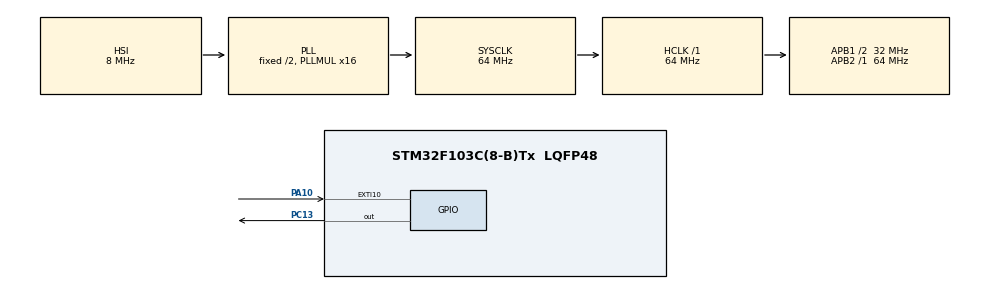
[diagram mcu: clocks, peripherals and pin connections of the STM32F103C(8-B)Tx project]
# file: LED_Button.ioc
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Mcu.Family=STM32F1
Mcu.Name=STM32F103C(8-B)Tx
Mcu.Package=LQFP48
NVIC.EXTI15_10_IRQn=true\:0\:0\:false\:false\:true\:true
NVIC.PriorityGroup=NVIC_PRIORITYGROUP_4
NVIC.TIM2_IRQn=true\:0\:0\:false\:false\:true\:true
PA10.GPIO_PuPd=GPIO_PULLUP
PA10.Signal=GPXTI10
PA13.Mode=Serial_Wire
PA13.Signal=SYS_JTMS-SWDIO
PA14.Mode=Serial_Wire
PA14.Signal=SYS_JTCK-SWCLK
PC13-TAMPER-RTC.Signal=GPIO_Output
ProjectManager.HeapSize=0x200
ProjectManager.StackSize=0x400
ProjectManager.TargetToolchain=TrueSTUDIO
RCC.AHBFreq_Value=64000000
RCC.APB1CLKDivider=RCC_HCLK_DIV2
RCC.APB1Freq_Value=32000000
RCC.APB1TimFreq_Value=64000000
RCC.APB2Freq_Value=64000000
RCC.APB2TimFreq_Value=64000000
RCC.HCLKFreq_Value=64000000
RCC.PLLMUL=RCC_PLL_MUL16
RCC.SYSCLKFreq_VALUE=64000000
RCC.SYSCLKSource=RCC_SYSCLKSOURCE_PLLCLK
RCC.USBFreq_Value=64000000
TIM2.Period=999
TIM2.Prescaler=31999
VP_TIM2_VS_ClockSourceINT.Mode=Internal
board=custom

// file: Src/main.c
/* USER CODE BEGIN Header */
/**
  ******************************************************************************
  * @file           : main.c
  * @brief          : Main program body
  ******************************************************************************
  ** This notice applies to any and all portions of this file
  * that are not between comment pairs USER CODE BEGIN and
  * USER CODE END. Other portions of this file, whether
  * inserted by the user or by software development tools
  * are owned by their respective copyright owners.
  *
  * COPYRIGHT(c) 2019 STMicroelectronics
  *
  * Redistribution and use in source and binary forms, with or without modification,
  * are permitted provided that the following conditions are met:
  *   1. Redistributions of source code must retain the above copyright notice,
  *      this list of conditions and the following disclaimer.
  *   2. Redistributions in binary form must reproduce the above copyright notice,
  *      this list of conditions and the following disclaimer in the documentation
  *      and/or other materials provided with the distribution.
  *   3. Neither the name of STMicroelectronics nor the names of its contributors
  *      may be used to endorse or promote products derived from this software
  *      without specific prior written permission.
  *
  * THIS SOFTWARE IS PROVIDED BY THE COPYRIGHT HOLDERS AND CONTRIBUTORS "AS IS"
  * AND ANY EXPRESS OR IMPLIED WARRANTIES, INCLUDING, BUT NOT LIMITED TO, THE
  * IMPLIED WARRANTIES OF MERCHANTABILITY AND FITNESS FOR A PARTICULAR PURPOSE ARE
  * DISCLAIMED. IN NO EVENT SHALL THE COPYRIGHT HOLDER OR CONTRIBUTORS BE LIABLE
  * FOR ANY DIRECT, INDIRECT, INCIDENTAL, SPECIAL, EXEMPLARY, OR CONSEQUENTIAL
  * DAMAGES (INCLUDING, BUT NOT LIMITED TO, PROCUREMENT OF SUBSTITUTE GOODS OR
  * SERVICES; LOSS OF USE, DATA, OR PROFITS; OR BUSINESS INTERRUPTION) HOWEVER
  * CAUSED AND ON ANY THEORY OF LIABILITY, WHETHER IN CONTRACT, STRICT LIABILITY,
  * OR TORT (INCLUDING NEGLIGENCE OR OTHERWISE) ARISING IN ANY WAY OUT OF THE USE
  * OF THIS SOFTWARE, EVEN IF ADVISED OF THE POSSIBILITY OF SUCH DAMAGE.
  *
  ******************************************************************************
  */
/* USER CODE END Header */

#include "main.h"

TIM_HandleTypeDef htim2;

void SystemClock_Config(void);
static void MX_GPIO_Init(void);
static void MX_TIM2_Init(void);

int main(void)
{

  /* MCU Configuration--------------------------------------------------------*/

  /* Reset of all peripherals, Initializes the Flash interface and the Systick. */
  HAL_Init();

  /* Configure the system clock */
  SystemClock_Config();

  /* Initialize all configured peripherals */
  MX_GPIO_Init();
  MX_TIM2_Init();
  /* USER CODE BEGIN 2 */
  HAL_TIM_Base_Start_IT(&htim2);
  /* USER CODE END 2 */

  /* Infinite loop */
  while (1)
  {

  }
}

void SystemClock_Config(void)
{
  RCC_OscInitTypeDef RCC_OscInitStruct = {0};
  RCC_ClkInitTypeDef RCC_ClkInitStruct = {0};

  /**Initializes the CPU, AHB and APB busses clocks
  */
  RCC_OscInitStruct.OscillatorType = RCC_OSCILLATORTYPE_HSI;
  RCC_OscInitStruct.HSIState = RCC_HSI_ON;
  RCC_OscInitStruct.HSICalibrationValue = RCC_HSICALIBRATION_DEFAULT;
  RCC_OscInitStruct.PLL.PLLState = RCC_PLL_ON;
  RCC_OscInitStruct.PLL.PLLSource = RCC_PLLSOURCE_HSI_DIV2;
  RCC_OscInitStruct.PLL.PLLMUL = RCC_PLL_MUL16;
  if (HAL_RCC_OscConfig(&RCC_OscInitStruct) != HAL_OK)
  {
    Error_Handler();
  }
  /**Initializes the CPU, AHB and APB busses clocks
  */
  RCC_ClkInitStruct.ClockType = RCC_CLOCKTYPE_HCLK|RCC_CLOCKTYPE_SYSCLK
                              |RCC_CLOCKTYPE_PCLK1|RCC_CLOCKTYPE_PCLK2;
  RCC_ClkInitStruct.SYSCLKSource = RCC_SYSCLKSOURCE_PLLCLK;
  RCC_ClkInitStruct.AHBCLKDivider = RCC_SYSCLK_DIV1;
  RCC_ClkInitStruct.APB1CLKDivider = RCC_HCLK_DIV2;
  RCC_ClkInitStruct.APB2CLKDivider = RCC_HCLK_DIV1;

  if (HAL_RCC_ClockConfig(&RCC_ClkInitStruct, FLASH_LATENCY_2) != HAL_OK)
  {
    Error_Handler();
  }
}

static void MX_TIM2_Init(void)
{

  TIM_ClockConfigTypeDef sClockSourceConfig = {0};
  TIM_MasterConfigTypeDef sMasterConfig = {0};

  htim2.Instance = TIM2;
  htim2.Init.Prescaler = 31999;
  htim2.Init.CounterMode = TIM_COUNTERMODE_UP;
  htim2.Init.Period = 999;
  htim2.Init.ClockDivision = TIM_CLOCKDIVISION_DIV1;
  htim2.Init.AutoReloadPreload = TIM_AUTORELOAD_PRELOAD_DISABLE;
  if (HAL_TIM_Base_Init(&htim2) != HAL_OK)
  {
    Error_Handler();
  }
  sClockSourceConfig.ClockSource = TIM_CLOCKSOURCE_INTERNAL;
  if (HAL_TIM_ConfigClockSource(&htim2, &sClockSourceConfig) != HAL_OK)
  {
    Error_Handler();
  }
  sMasterConfig.MasterOutputTrigger = TIM_TRGO_RESET;
  sMasterConfig.MasterSlaveMode = TIM_MASTERSLAVEMODE_DISABLE;
  if (HAL_TIMEx_MasterConfigSynchronization(&htim2, &sMasterConfig) != HAL_OK)
  {
    Error_Handler();
  }

}

static void MX_GPIO_Init(void)
{
  GPIO_InitTypeDef GPIO_InitStruct = {0};

  /* GPIO Ports Clock Enable */
  __HAL_RCC_GPIOC_CLK_ENABLE();
  __HAL_RCC_GPIOA_CLK_ENABLE();

  /*Configure GPIO pin Output Level */
  HAL_GPIO_WritePin(GPIOC, GPIO_PIN_13, GPIO_PIN_RESET);

  /*Configure GPIO pin : PC13 */
  GPIO_InitStruct.Pin = GPIO_PIN_13;
  GPIO_InitStruct.Mode = GPIO_MODE_OUTPUT_PP;
  GPIO_InitStruct.Pull = GPIO_NOPULL;
  GPIO_InitStruct.Speed = GPIO_SPEED_FREQ_LOW;
  HAL_GPIO_Init(GPIOC, &GPIO_InitStruct);

  /*Configure GPIO pin : PA10 */
  GPIO_InitStruct.Pin = GPIO_PIN_10;
  GPIO_InitStruct.Mode = GPIO_MODE_IT_RISING;
  GPIO_InitStruct.Pull = GPIO_PULLUP;
  HAL_GPIO_Init(GPIOA, &GPIO_InitStruct);

  /* EXTI interrupt init*/
  HAL_NVIC_SetPriority(EXTI15_10_IRQn, 0, 0);
  HAL_NVIC_EnableIRQ(EXTI15_10_IRQn);

}

/* USER CODE BEGIN 4 */
void enciende_LED(void)
{
	HAL_GPIO_TogglePin(GPIOC, GPIO_PIN_13);
}
/* USER CODE END 4 */

void Error_Handler(void)
{
}

/************************ (C) COPYRIGHT STMicroelectronics *****END OF FILE****/
